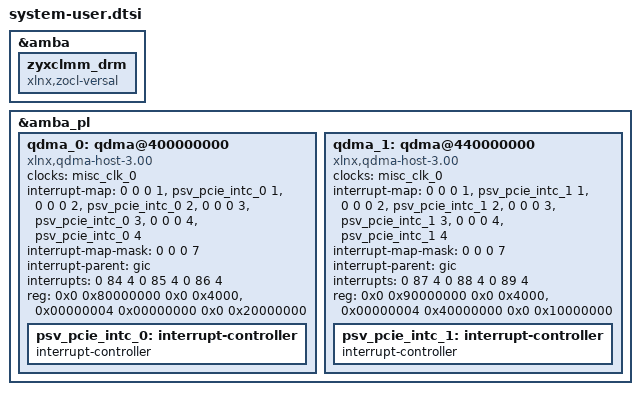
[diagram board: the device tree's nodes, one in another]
/include/ "system-conf.dtsi"
/ {
};

&amba {
        zyxclmm_drm {
                compatible = "xlnx,zocl-versal";
        };
};

&amba_pl {

	/delete-node/ qdma@80000000;
	/delete-node/ qdma@90000000;

qdma_0: qdma@400000000 {
	#address-cells = <3>;
	#interrupt-cells = <1>;
	#size-cells = <2>;
	clock-names = "user_clk_sd";
	clocks = <&misc_clk_0>;
	compatible = "xlnx,qdma-host-3.00";
	device_type = "pci";
	interrupt-map = <0 0 0 1 &psv_pcie_intc_0 1>, <0 0 0 2 &psv_pcie_intc_0 2>, <0 0 0 3 &psv_pcie_intc_0 3>, <0 0 0 4 &psv_pcie_intc_0 4>;
	interrupt-map-mask = <0 0 0 7>;
	interrupt-names = "misc", "msi0", "msi1";
	interrupt-parent = <&gic>;
	interrupts = <0 84 4 0 85 4 0 86 4>;
	ranges = <0x02000000 0x00000000 0xA8000000 0x0 0xA8000000 0x00000000 0x08000000>;
	reg = <0x0 0x80000000 0x0 0x4000>, <0x00000004 0x00000000 0x0 0x20000000>;
	reg-names = "breg", "cfg";
	psv_pcie_intc_0: interrupt-controller {
		#address-cells = <0>;
		#interrupt-cells = <1>;
		interrupt-controller ;
	};
};

qdma_1: qdma@440000000 {
	#address-cells = <3>;
	#interrupt-cells = <1>;
	#size-cells = <2>;
	clock-names = "user_clk_sd";
	clocks = <&misc_clk_0>;
	compatible = "xlnx,qdma-host-3.00";
	device_type = "pci";
	interrupt-map = <0 0 0 1 &psv_pcie_intc_1 1>, <0 0 0 2 &psv_pcie_intc_1 2>, <0 0 0 3 &psv_pcie_intc_1 3>, <0 0 0 4 &psv_pcie_intc_1 4>;
	interrupt-map-mask = <0 0 0 7>;
	interrupt-names = "misc", "msi0", "msi1";
	interrupt-parent = <&gic>;
	interrupts = <0 87 4 0 88 4 0 89 4>;
	ranges = <0x02000000 0x00000000 0xB0000000 0x0 0xB0000000 0x00000000 0x10000000>;
	reg = <0x0 0x90000000 0x0 0x4000>, <0x00000004 0x40000000 0x0 0x10000000>;
	reg-names = "breg", "cfg";
	psv_pcie_intc_1: interrupt-controller {
		#address-cells = <0>;
		#interrupt-cells = <1>;
		interrupt-controller ;
	};
};

};

